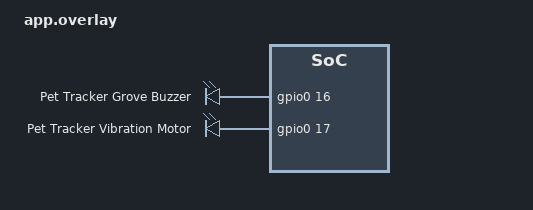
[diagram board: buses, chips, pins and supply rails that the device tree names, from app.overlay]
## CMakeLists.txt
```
cmake_minimum_required(VERSION 3.20.0)

find_package(Zephyr REQUIRED HINTS $ENV{ZEPHYR_BASE})
project(pet_tracker_firmware VERSION 0.1.0 LANGUAGES C)

target_include_directories(app PRIVATE src)

target_sources(app PRIVATE
    src/main.c
    src/app/app_config.c
    src/app/app_state.c
    src/drivers/buzzer.c
    src/drivers/vibration_motor.c
    src/platform/diagnostics.c
)
```

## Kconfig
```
source "Kconfig.zephyr"

menu "Pet Tracker firmware"

config PET_TRACKER_FIRMWARE_VERSION
    string "Pet Tracker firmware version"
    default "0.1.0"

config PET_TRACKER_HEARTBEAT_INTERVAL_SECONDS
    int "Boot heartbeat interval in seconds"
    default 60
    range 5 3600
    help
      Interval used by the MVP main loop to prove the device is alive without
      busy polling.

config PET_TRACKER_BUZZER
    bool "Enable Grove active buzzer driver"
    default n
    help
      Enable GPIO control for the prototype Grove active buzzer on the
      devicetree alias buzzer0.

config PET_TRACKER_BUZZER_STARTUP_TONE
    bool "Run buzzer startup tone on boot"
    depends on PET_TRACKER_BUZZER
    default n
    help
      Emit one short startup tone during boot for V0 hardware bring-up.

config PET_TRACKER_VIBRATION_MOTOR
    bool "Enable vibration motor driver"
    default n
    help
      Enable GPIO control for the prototype vibration motor MOSFET on the
      devicetree alias vibration0.

config PET_TRACKER_VIBRATION_MAX_PULSE_MS
    int "Maximum vibration pulse duration in milliseconds"
    depends on PET_TRACKER_VIBRATION_MOTOR
    default 500
    range 50 2000
    help
      Maximum duration for one vibration pulse. This protects the prototype
      from accidental long motor activation.

config PET_TRACKER_VIBRATION_BOOT_TEST
    bool "Run a short vibration pulse on boot"
    depends on PET_TRACKER_VIBRATION_MOTOR
    default n
    help
      Emit one short vibration pulse during boot for manual V0 hardware
      bring-up. Keep disabled unless the motor driver circuit has been checked.

config PET_TRACKER_VIBRATION_BOOT_TEST_MS
    int "Vibration boot test pulse duration in milliseconds"
    depends on PET_TRACKER_VIBRATION_MOTOR
    default 1000
    range 50 1000
    help
      Duration of the optional boot test pulse.

config PET_TRACKER_VIBRATION_BOOT_TEST_REPEATS
    int "Vibration boot test pulse repeat count"
    depends on PET_TRACKER_VIBRATION_MOTOR
    default 3
    range 1 5
    help
      Number of boot test pulses. Use multiple pulses during V0 bring-up so
      the MOSFET gate can be checked with a multimeter.

endmenu
```

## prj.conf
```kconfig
CONFIG_LOG=y
CONFIG_LOG_DEFAULT_LEVEL=3
CONFIG_MAIN_STACK_SIZE=2048

CONFIG_PET_TRACKER_FIRMWARE_VERSION="0.1.0"
CONFIG_PET_TRACKER_HEARTBEAT_INTERVAL_SECONDS=60
CONFIG_PET_TRACKER_BUZZER=y
# CONFIG_PET_TRACKER_BUZZER_STARTUP_TONE=y
CONFIG_PET_TRACKER_VIBRATION_MOTOR=y
# Enable only after wiring the MOSFET, pull-down resistor, and flyback diode.
# CONFIG_PET_TRACKER_VIBRATION_BOOT_TEST=y
```

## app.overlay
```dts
#include <zephyr/dt-bindings/gpio/gpio.h>

/ {
	aliases {
		buzzer0 = &pet_tracker_buzzer;
		vibration0 = &pet_tracker_vibration;
	};

	pet_tracker_outputs {
		compatible = "gpio-leds";

		pet_tracker_buzzer: buzzer {
			gpios = <&gpio0 16 GPIO_ACTIVE_HIGH>;
			label = "Pet Tracker Grove Buzzer";
		};

		pet_tracker_vibration: vibration {
			gpios = <&gpio0 17 GPIO_ACTIVE_HIGH>;
			label = "Pet Tracker Vibration Motor";
		};
	};
};
```

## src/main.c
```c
#include <zephyr/kernel.h>
#include <zephyr/logging/log.h>

#include "app/app_state.h"
#include "drivers/buzzer.h"
#include "drivers/vibration_motor.h"
#include "platform/diagnostics.h"

LOG_MODULE_REGISTER(main, LOG_LEVEL_INF);

int main(void)
{
	diagnostics_log_boot_banner();

	if (app_state_init(DEVICE_STATE_BOOT) != 0) {
		return 0;
	}

	if (app_state_transition(DEVICE_STATE_IDLE, "boot complete") != 0) {
		return 0;
	}

	if (IS_ENABLED(CONFIG_PET_TRACKER_BUZZER)) {
		int err = buzzer_init();

		if (err != 0) {
			LOG_ERR("Buzzer init failed: %d", err);
		} else if (IS_ENABLED(CONFIG_PET_TRACKER_BUZZER_STARTUP_TONE)) {
			LOG_INF("Running buzzer startup tone");
			err = buzzer_startup_tone();
			if (err != 0) {
				LOG_ERR("Buzzer startup tone failed: %d", err);
			} else {
				LOG_INF("Buzzer startup tone complete");
			}
		}
	}

	if (IS_ENABLED(CONFIG_PET_TRACKER_VIBRATION_MOTOR)) {
		int err = vibration_motor_init();

		if (err != 0) {
			LOG_ERR("Vibration motor init failed: %d", err);
		} else if (IS_ENABLED(CONFIG_PET_TRACKER_VIBRATION_BOOT_TEST)) {
			LOG_INF("Running vibration motor boot test");
			for (int i = 0; i < CONFIG_PET_TRACKER_VIBRATION_BOOT_TEST_REPEATS; i++) {
				LOG_INF("Vibration motor boot test pulse %d/%d",
					i + 1,
					CONFIG_PET_TRACKER_VIBRATION_BOOT_TEST_REPEATS);
				err = vibration_motor_pulse_ms(CONFIG_PET_TRACKER_VIBRATION_BOOT_TEST_MS);
				if (err != 0) {
					LOG_ERR("Vibration motor boot test failed: %d", err);
					break;
				}
				k_msleep(500);
			}
			if (err == 0) {
				LOG_INF("Vibration motor boot test complete");
			}
		}
	}

	for (;;) {
		LOG_INF("Heartbeat: state=%s", app_state_name(app_state_get()));
		k_sleep(K_SECONDS(CONFIG_PET_TRACKER_HEARTBEAT_INTERVAL_SECONDS));
	}

	return 0;
}
```
